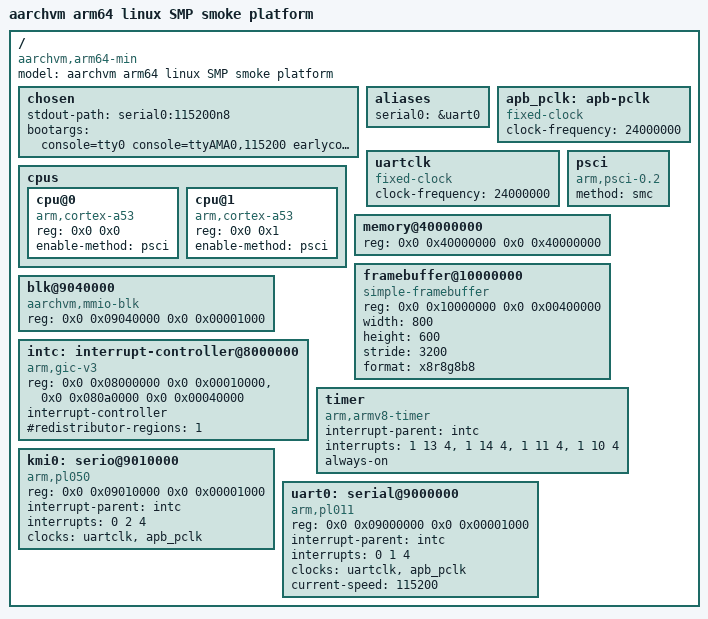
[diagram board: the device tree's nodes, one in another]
/dts-v1/;

/ {
	model = "aarchvm arm64 linux SMP smoke platform";
	compatible = "aarchvm,arm64-min";
	#address-cells = <2>;
	#size-cells = <2>;

	chosen {
		stdout-path = "serial0:115200n8";
		bootargs = "console=tty0 console=ttyAMA0,115200 earlycon=pl011,0x09000000";
	};

	aliases {
		serial0 = &uart0;
	};

	apb_pclk: apb-pclk {
		compatible = "fixed-clock";
		#clock-cells = <0>;
		clock-frequency = <24000000>;
	};

	uartclk: uartclk {
		compatible = "fixed-clock";
		#clock-cells = <0>;
		clock-frequency = <24000000>;
	};

	cpus {
		#address-cells = <2>;
		#size-cells = <0>;

		cpu@0 {
			device_type = "cpu";
			compatible = "arm,cortex-a53";
			reg = <0x0 0x0>;
			enable-method = "psci";
		};

		cpu@1 {
			device_type = "cpu";
			compatible = "arm,cortex-a53";
			reg = <0x0 0x1>;
			enable-method = "psci";
		};
	};

	psci {
		compatible = "arm,psci-0.2";
		method = "smc";
	};

	memory@40000000 {
		device_type = "memory";
		reg = <0x0 0x40000000 0x0 0x40000000>;
	};

	framebuffer@10000000 {
		compatible = "simple-framebuffer";
		reg = <0x0 0x10000000 0x0 0x00400000>;
		width = <800>;
		height = <600>;
		stride = <3200>;
		format = "x8r8g8b8";
		status = "okay";
	};

	blk@9040000 {
		compatible = "aarchvm,mmio-blk";
		reg = <0x0 0x09040000 0x0 0x00001000>;
		status = "okay";
	};

	intc: interrupt-controller@8000000 {
		compatible = "arm,gic-v3";
		reg = <0x0 0x08000000 0x0 0x00010000>,
		      <0x0 0x080a0000 0x0 0x00040000>;
		interrupt-controller;
		#interrupt-cells = <3>;
		#address-cells = <2>;
		#size-cells = <2>;
		#redistributor-regions = <1>;
		ranges;
	};

	timer {
		compatible = "arm,armv8-timer";
		interrupt-parent = <&intc>;
		interrupts = <1 13 4>, <1 14 4>, <1 11 4>, <1 10 4>;
		always-on;
	};

	kmi0: serio@9010000 {
		compatible = "arm,pl050", "arm,primecell";
		reg = <0x0 0x09010000 0x0 0x00001000>;
		interrupt-parent = <&intc>;
		interrupts = <0 2 4>;
		clocks = <&uartclk>, <&apb_pclk>;
		clock-names = "KMIREFCLK", "apb_pclk";
		status = "okay";
	};

	uart0: serial@9000000 {
		compatible = "arm,pl011", "arm,primecell";
		reg = <0x0 0x09000000 0x0 0x00001000>;
		interrupt-parent = <&intc>;
		interrupts = <0 1 4>;
		clocks = <&uartclk>, <&apb_pclk>;
		clock-names = "uartclk", "apb_pclk";
		current-speed = <115200>;
		status = "okay";
	};
};
